# BAT32G157 register map
Vendor: Cmsemicon; Series: BAT32G157; File version: 1.0
CPU: CM0+ r0p1, little endian, no MPU, no FPU, VTOR, 2 interrupt priority bits
Registers are 8-bit, read-write, reset 0x0 unless marked. A register's access mark holds for its fields unless they carry their own. Offsets are from the block's base; [hi:lo] are bit positions; {n}, {i} and the like mark numbered series; 'fields as' and 'values as' point back to an identical list.

## CMP — Comparator
Base 0x40043840
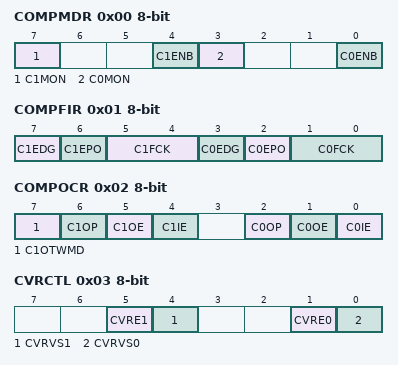
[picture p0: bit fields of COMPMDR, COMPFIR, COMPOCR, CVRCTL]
0x00 COMPMDR — Comparator mode setting register
  [7] C1MON — Comparator 1 monitor flag
  [4] C1ENB — Comparator 1 operation enable
  [3] C0MON — Comparator 0 monitor flag
  [0] C0ENB — Comparator 0 operation 1enable
0x01 COMPFIR — Comparator filter control register
  [7] C1EDG — Comparator 1 edge detection selection
  [6] C1EPO — Comparator 1 edge polarity switching
  [5:4] C1FCK — Comparator 1 filter selection
  [3] C0EDG — Comparator 0 edge detection selection
  [2] C0EPO — Comparator 0 edge polarity switching
  [1:0] C0FCK — Comparator 0 filter selection
0x02 COMPOCR — Comparator output control register
  [7] C1OTWMD — TIMER WINDOW output mode control bit of comparator 1
  [6] C1OP — VOUT1 output polarity selection
  [5] C1OE — VOUT1 pin output enable
  [4] C1IE — Comparator 1 interrupt request enable
  [2] C0OP — VOUT0 output polarity selection
  [1] C0OE — VOUT0 pin output enable
  [0] C0IE — Comparator 0 interrupt request enable
0x03 CVRCTL — Comparator internal reference voltage control register
  [5] CVRE1 — Control bit for internal reference voltage 1
  [4] CVRVS1 — Ground selection bit for internal reference voltage
  [1] CVRE0 — Control bit for internal reference voltage 0
  [0] CVRVS0 — Power supply selection bit for internal reference voltage
0x04 C0RVM — Comparator internal reference voltage select register 0
0x05 C1RVM — Comparator internal reference voltage select register 1
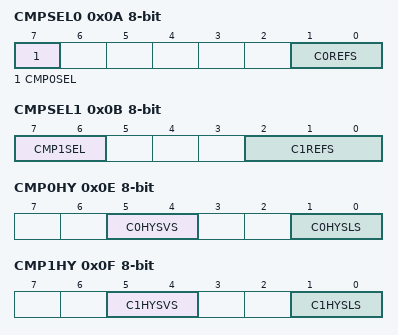
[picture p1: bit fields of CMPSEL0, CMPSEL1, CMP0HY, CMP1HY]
0x0A CMPSEL0 — Comparator 0 input signal selection control register
  [7] CMP0SEL — Selection of the input signal on the positive side of Comparator 0
  [1:0] C0REFS — Selection of the input signal on the negative side of Comparator 0
0x0B CMPSEL1 — Comparator 1 input signal selection control register
  [7:6] CMP1SEL — Selection of the input signal on the positive side of Comparator 1
  [2:0] C1REFS — Selection of the input signal on the negative side of Comparator 1
0x0E CMP0HY — Comparator 0 input voltage hysteresis control register
  [5:4] C0HYSVS — Selection of the input hysteresis voltage of Comparator 0
  [1:0] C0HYSLS — Selection of the input hysteresis voltage level of Comparator 0
0x0F CMP1HY — Comparator 1 input voltage hysteresis control register
  [5:4] C1HYSVS — Selection of the input hysteresis voltage of Comparator 1
  [1:0] C1HYSLS — Selection of the input hysteresis voltage level of Comparator 1

## PGA — Programmable Gain Amplifier
Base 0x40043840; alternate view of CMP
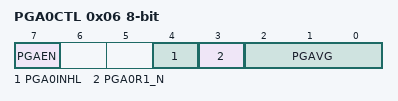
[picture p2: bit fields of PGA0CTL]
0x06 PGA0CTL — PGA 0 control register
  [7] PGAEN — Programmable gain amplifier operation control
  [4] PGA0INHL — PGA0IN and PGA0GNA input selection of the programmable gain amplifier
  [3] PGA0R1_N — Differential or single-ended input selection of the programmable gain amplifier
  [2:0] PGAVG — Programmable gain amplifier amplification factor selection

## SCI0 — Serial Communication Interface 0 with UART, SPI and simplified I2C supported
Base 0x40041000
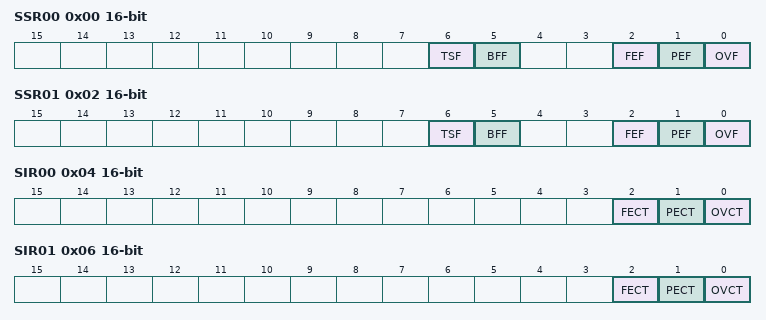
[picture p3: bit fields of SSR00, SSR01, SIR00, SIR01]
0x00 SSR00 16-bit ro — Serial status register mn
  [6] TSF — Communication status indication flag of channel n
  [5] BFF — Buffer register status indication flag of channel n
  [2] FEF — Framing error detection flag of channel n
  [1] PEF — Parity error detection flag of channel n
  [0] OVF — Overrun error detection flag of channel n
0x02 SSR01 16-bit ro — Serial status register mn
  fields as SSR00
0x04 SIR00 16-bit — Serial flag clear trigger register mn
  [2] FECT — Clear trigger of framing error flag of channel n
  [1] PECT — Clear trigger of parity error flag of channel n
  [0] OVCT — Clear trigger of overrun error flag of channel n
0x06 SIR01 16-bit — Serial flag clear trigger register mn
  fields as SIR00
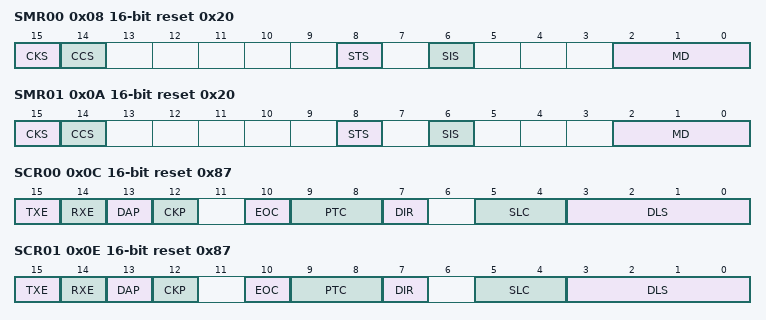
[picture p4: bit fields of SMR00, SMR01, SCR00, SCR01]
0x08 SMR00 16-bit reset 0x20 — Serial mode register mn
  [15] CKS — Selection of operation clock (fMCK) of channel n
  [14] CCS — Selection of transfer clock (fTCLK) of channel n
  [8] STS — Selection of start trigger source
  [6] SIS — Controls inversion of level of receive data of channel n in UART mode
  [2:0] MD — Setting of operation mode of channel n
0x0A SMR01 16-bit reset 0x20 — Serial mode register mn
  fields as SMR00
0x0C SCR00 16-bit reset 0x87 — Serial communication operation setting register mn
  [15] TXE — Transmission enable
  [14] RXE — Reception enable
  [13] DAP — Selection of data phase in SPI mode
  [12] CKP — Selection of clock phase in SPI mode
  [10] EOC — Mask control of error interrupt signal (INTSREx (x = 0 to 2))
  [9:8] PTC — Setting of parity bit in UART mode
  [7] DIR — Selection of data transfer sequence in SPI and UART modes
  [5:4] SLC — Setting of stop bit in UART mode
  [3:0] DLS — Setting of data length in SPI and UART modes
0x0E SCR01 16-bit reset 0x87 — Serial communication operation setting register mn
  fields as SCR00
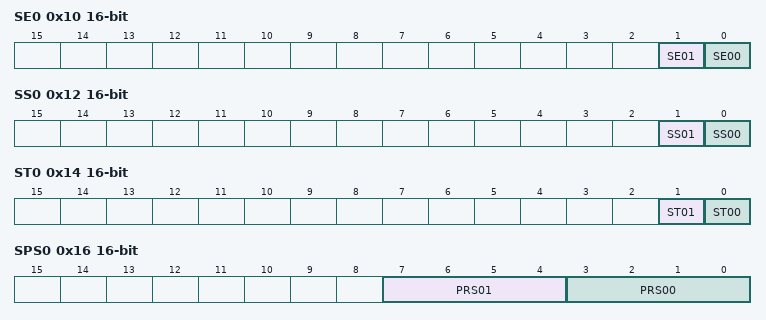
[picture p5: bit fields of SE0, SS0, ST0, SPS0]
0x10 SE0 16-bit ro — Serial channel enable status register m
  [1] SE01 — Indication of operation enable/stop status of channel 1
  [0] SE00 — Indication of operation enable/stop status of channel 0
0x12 SS0 16-bit — Serial channel start register 0
  [1] SS01 — Operation start trigger of channel 1
  [0] SS00 — Operation start trigger of channel 0
0x14 ST0 16-bit — Serial channel stop register 0
  [1] ST01 — Operation stop trigger of channel 1
  [0] ST00 — Operation stop trigger of channel 0
0x16 SPS0 16-bit — Serial clock select register 0
  [7:4] PRS01 — Prescaler 1
  [3:0] PRS00 — Prescaler 0
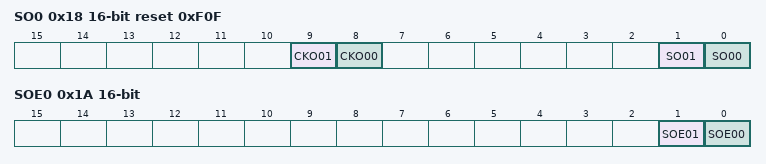
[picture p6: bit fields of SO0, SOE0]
0x18 SO0 16-bit reset 0xF0F — Serial output register 0
  [9] CKO01 — Serial clock output of channel 1
  [8] CKO00 — Serial clock output of channel 0
  [1] SO01 — Serial data output of channel 1
  [0] SO00 — Serial data output of channel 0
0x1A SOE0 16-bit — Serial output enable register 0
  [1] SOE01 — Serial output enable of channel 1
  [0] SOE00 — Serial output enable of channel 0
0x20 SOL0 16-bit — Serial output level register 0
  [0] SOL00 — Selects inversion of the level of the transmit data of channel n in UART mode
{0x110+2i} SDR0{i} (i=0..1) 16-bit — Serial data register 0{i}
0x110 SIO00 (alternate view of SDR00) — SPI data register
0x110 TXD0 (alternate view of SDR00) — UART transmit data register
0x112 SIO01 (alternate view of SDR01) — SPI data register
0x112 RXD0 (alternate view of SDR01) — UART receive data register
